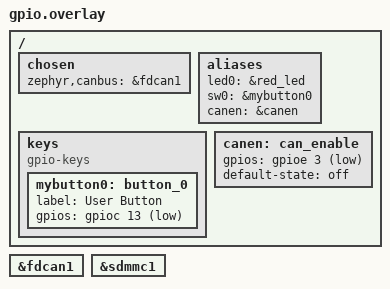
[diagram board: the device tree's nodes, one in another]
/ {
    chosen {
        zephyr,canbus = &fdcan1;  // use your CAN controller here
    };

    aliases {
            led0 = &red_led;
            sw0 = &mybutton0;  // Link sw0 alias to your button
            canen = &canen;
    };

    keys {
        compatible = "gpio-keys";
        
        mybutton0: button_0 {
            label = "User Button";
            gpios = <&gpioc 13 (GPIO_PULL_UP | GPIO_ACTIVE_LOW)>;
        };
    };
    canen: can_enable {
			gpios = <&gpioe 3 GPIO_ACTIVE_LOW>;
            default-state = "off";
    };

};
&fdcan1 {
    status = "okay";
};
&sdmmc1{
    status = "okay";
};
